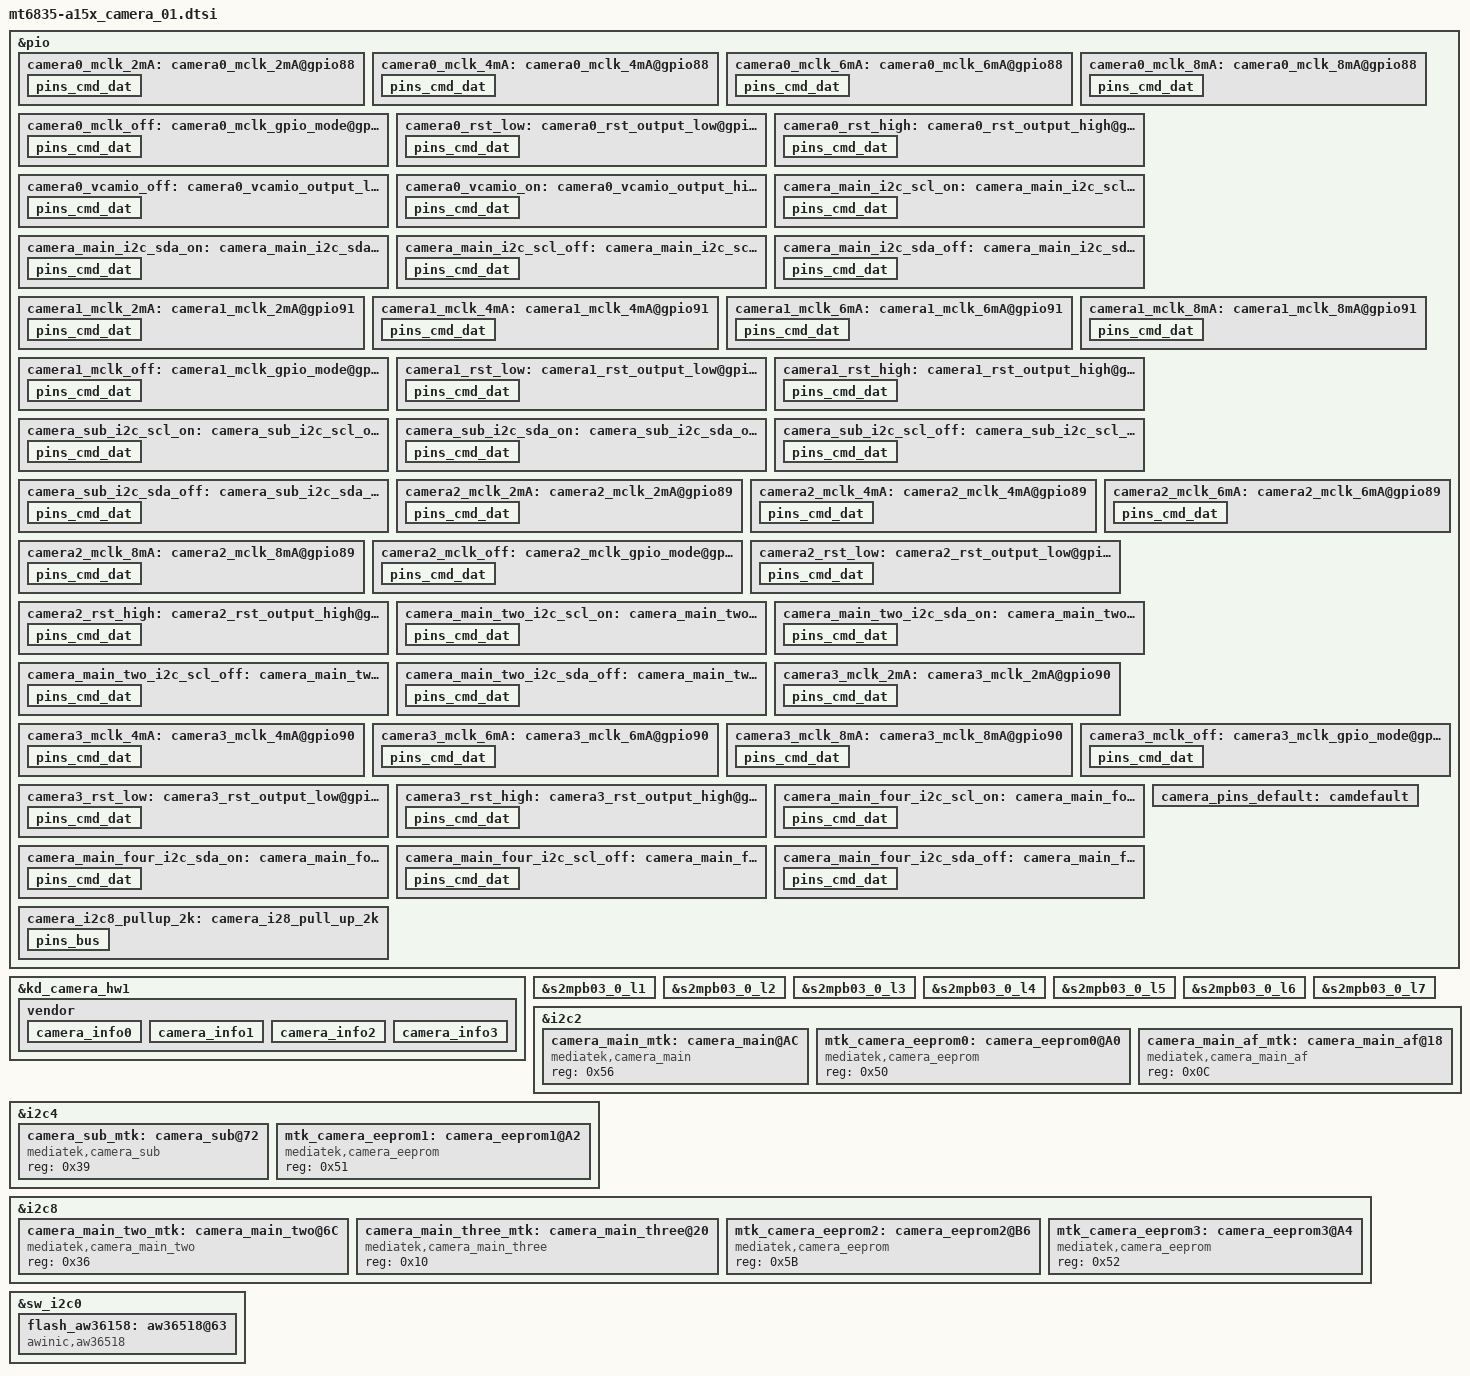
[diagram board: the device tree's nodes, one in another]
/*
 * Copyright (c) 2023 MediaTek Inc.
 *
 * This program is free software; you can redistribute it and/or modify
 * it under the terms of the GNU General Public License version 2 as
 * published by the Free Software Foundation.
 *
 * This program is distributed in the hope that it will be useful,
 * but WITHOUT ANY WARRANTY; without even the implied warranty of
 * MERCHANTABILITY or FITNESS FOR A PARTICULAR PURPOSE.  See the
 * GNU General Public License for more details.
 */

/********  A15-5G Board  ***********
 *    SW          :   HW   : Sensor
 * camera0(Wide)  : RCAM1  : HI5022Q or S5KJN1
 * camera1(Front) : FCAM   : GC13A0
 * camera2(UW)    : RCAM2  : SC501CS
 * camera3(Macro) : RCAM3  : GC02M2
 ***********************************/

/* CAMERA GPIO standardization */
&pio {
	/****************  Camera0  ***************/
	// MCLK
	camera0_mclk_2mA: camera0_mclk_2mA@gpio88 {
		pins_cmd_dat {
			pinmux = <PINMUX_GPIO88__FUNC_CMMCLK0>;
			drive-strength = <0>;
		};
	};
	camera0_mclk_4mA: camera0_mclk_4mA@gpio88 {
		pins_cmd_dat {
			pinmux = <PINMUX_GPIO88__FUNC_CMMCLK0>;
			drive-strength = <1>;
		};
	};
	camera0_mclk_6mA: camera0_mclk_6mA@gpio88 {
		pins_cmd_dat {
			pinmux = <PINMUX_GPIO88__FUNC_CMMCLK0>;
			drive-strength = <2>;
		};
	};
	camera0_mclk_8mA: camera0_mclk_8mA@gpio88 {
		pins_cmd_dat {
			pinmux = <PINMUX_GPIO88__FUNC_CMMCLK0>;
			drive-strength = <3>;
		};
	};
	camera0_mclk_off: camera0_mclk_gpio_mode@gpio88 {
		pins_cmd_dat {
			pinmux = <PINMUX_GPIO88__FUNC_GPIO88>;
			drive-strength = <1>;
		};
	};

	// Reset
	camera0_rst_low: camera0_rst_output_low@gpio25 {
		pins_cmd_dat {
			pinmux = <PINMUX_GPIO25__FUNC_GPIO25>;
			output-low;
		};
	};
	camera0_rst_high: camera0_rst_output_high@gpio25 {
		pins_cmd_dat {
			pinmux = <PINMUX_GPIO25__FUNC_GPIO25>;
			output-high;
		};
	};

	// IOVDD
	camera0_vcamio_off: camera0_vcamio_output_low@gpio150 {
		pins_cmd_dat {
			pinmux = <PINMUX_GPIO150__FUNC_GPIO150>;
			output-low;
		};
	};
	camera0_vcamio_on: camera0_vcamio_output_high@gpio150 {
		pins_cmd_dat {
			pinmux = <PINMUX_GPIO150__FUNC_GPIO150>;
			output-high;
		};
	};

	// I2C
	camera_main_i2c_scl_on: camera_main_i2c_scl_on@gpio131 {
		pins_cmd_dat {
			pinmux = <PINMUX_GPIO131__FUNC_SCL2>;
			bias-disable;
		};
	};
	camera_main_i2c_sda_on: camera_main_i2c_sda_on@gpio132 {
		pins_cmd_dat {
			pinmux = <PINMUX_GPIO132__FUNC_SDA2>;
			bias-disable;
		};
	};
	camera_main_i2c_scl_off: camera_main_i2c_scl_off@gpio131 {
		pins_cmd_dat {
			pinmux = <PINMUX_GPIO131__FUNC_GPIO131>;
			bias-disable;
		};
	};
	camera_main_i2c_sda_off: camera_main_i2c_sda_off@gpio132 {
		pins_cmd_dat {
			pinmux = <PINMUX_GPIO132__FUNC_GPIO132>;
			bias-disable;
		};
	};

	/****************  Camera1  ***************/
	// MCLK
	camera1_mclk_2mA: camera1_mclk_2mA@gpio91 {
		pins_cmd_dat {
			pinmux = <PINMUX_GPIO91__FUNC_CMMCLK3>;
			drive-strength = <0>;
		};
	};
	camera1_mclk_4mA: camera1_mclk_4mA@gpio91 {
		pins_cmd_dat {
			pinmux = <PINMUX_GPIO91__FUNC_CMMCLK3>;
			drive-strength = <1>;
		};
	};
	camera1_mclk_6mA: camera1_mclk_6mA@gpio91 {
		pins_cmd_dat {
			pinmux = <PINMUX_GPIO91__FUNC_CMMCLK3>;
			drive-strength = <2>;
		};
	};
	camera1_mclk_8mA: camera1_mclk_8mA@gpio91 {
		pins_cmd_dat {
			pinmux = <PINMUX_GPIO91__FUNC_CMMCLK3>;
			drive-strength = <3>;
		};
	};
	camera1_mclk_off: camera1_mclk_gpio_mode@gpio91 {
		pins_cmd_dat {
			pinmux = <PINMUX_GPIO91__FUNC_GPIO91>;
			drive-strength = <1>;
		};
	};

	// Reset
	camera1_rst_low: camera1_rst_output_low@gpio21 {
		pins_cmd_dat {
			pinmux = <PINMUX_GPIO21__FUNC_GPIO21>;
			output-low;
		};
	};
	camera1_rst_high: camera1_rst_output_high@gpio21 {
		pins_cmd_dat {
			pinmux = <PINMUX_GPIO21__FUNC_GPIO21>;
			output-high;
		};
	};

	// I2C
	camera_sub_i2c_scl_on: camera_sub_i2c_scl_on@gpio135 {
		pins_cmd_dat {
			pinmux = <PINMUX_GPIO135__FUNC_SCL4>;
			bias-pull-up;
		};
	};
	camera_sub_i2c_sda_on: camera_sub_i2c_sda_on@gpio136 {
		pins_cmd_dat {
			pinmux = <PINMUX_GPIO136__FUNC_SDA4>;
			bias-pull-up;
		};
	};
	camera_sub_i2c_scl_off: camera_sub_i2c_scl_off@gpio135 {
		pins_cmd_dat {
			pinmux = <PINMUX_GPIO135__FUNC_GPIO135>;
			bias-pull-down;
		};
	};
	camera_sub_i2c_sda_off: camera_sub_i2c_sda_off@gpio136 {
		pins_cmd_dat {
			pinmux = <PINMUX_GPIO136__FUNC_GPIO136>;
			bias-pull-down;
		};
	};

	/****************  Camera2  ***************/
	// MCLK
	camera2_mclk_2mA: camera2_mclk_2mA@gpio89 {
		pins_cmd_dat {
			pinmux = <PINMUX_GPIO89__FUNC_CMMCLK1>;
			drive-strength = <0>;
		};
	};
	camera2_mclk_4mA: camera2_mclk_4mA@gpio89 {
		pins_cmd_dat {
			pinmux = <PINMUX_GPIO89__FUNC_CMMCLK1>;
			drive-strength = <1>;
		};
	};
	camera2_mclk_6mA: camera2_mclk_6mA@gpio89 {
		pins_cmd_dat {
			pinmux = <PINMUX_GPIO89__FUNC_CMMCLK1>;
			drive-strength = <2>;
		};
	};
	camera2_mclk_8mA: camera2_mclk_8mA@gpio89 {
		pins_cmd_dat {
			pinmux = <PINMUX_GPIO89__FUNC_CMMCLK1>;
			drive-strength = <3>;
		};
	};
	camera2_mclk_off: camera2_mclk_gpio_mode@gpio89 {
		pins_cmd_dat {
			pinmux = <PINMUX_GPIO89__FUNC_GPIO89>;
			drive-strength = <1>;
		};
	};

	// Reset
	camera2_rst_low: camera2_rst_output_low@gpio27 {
		pins_cmd_dat {
			pinmux = <PINMUX_GPIO27__FUNC_GPIO27>;
			output-low;
		};
	};
	camera2_rst_high: camera2_rst_output_high@gpio27 {
		pins_cmd_dat {
			pinmux = <PINMUX_GPIO27__FUNC_GPIO27>;
			output-high;
		};
	};

	// I2C
	camera_main_two_i2c_scl_on: camera_main_two_i2c_scl_on@gpio143 {
		pins_cmd_dat {
			pinmux = <PINMUX_GPIO143__FUNC_SCL8>;
			bias-pull-up;
		};
	};
	camera_main_two_i2c_sda_on: camera_main_two_i2c_sda_on@gpio144 {
		pins_cmd_dat {
			pinmux = <PINMUX_GPIO144__FUNC_SDA8>;
			bias-pull-up;
		};
	};
	camera_main_two_i2c_scl_off: camera_main_two_i2c_scl_off@gpio143 {
		pins_cmd_dat {
			pinmux = <PINMUX_GPIO143__FUNC_GPIO143>;
			bias-pull-down;
		};
	};
	camera_main_two_i2c_sda_off: camera_main_two_i2c_sda_off@gpio144 {
		pins_cmd_dat {
			pinmux = <PINMUX_GPIO144__FUNC_GPIO144>;
			bias-pull-down;
		};
	};

	/****************  Camera3  ***************/
	// MCLK
	camera3_mclk_2mA: camera3_mclk_2mA@gpio90 {
		pins_cmd_dat {
			pinmux = <PINMUX_GPIO90__FUNC_CMMCLK2>;
			drive-strength = <0>;
		};
	};
	camera3_mclk_4mA: camera3_mclk_4mA@gpio90 {
		pins_cmd_dat {
			pinmux = <PINMUX_GPIO90__FUNC_CMMCLK2>;
			drive-strength = <1>;
		};
	};
	camera3_mclk_6mA: camera3_mclk_6mA@gpio90 {
		pins_cmd_dat {
			pinmux = <PINMUX_GPIO90__FUNC_CMMCLK2>;
			drive-strength = <2>;
		};
	};
	camera3_mclk_8mA: camera3_mclk_8mA@gpio90 {
		pins_cmd_dat {
			pinmux = <PINMUX_GPIO90__FUNC_CMMCLK2>;
			drive-strength = <3>;
		};
	};
	camera3_mclk_off: camera3_mclk_gpio_mode@gpio90 {
		pins_cmd_dat {
			pinmux = <PINMUX_GPIO90__FUNC_GPIO90>;
			drive-strength = <1>;
		};
	};

	// Reset
	camera3_rst_low: camera3_rst_output_low@gpio26 {
		pins_cmd_dat {
			pinmux = <PINMUX_GPIO26__FUNC_GPIO26>;
			output-low;
		};
	};
	camera3_rst_high: camera3_rst_output_high@gpio26 {
		pins_cmd_dat {
			pinmux = <PINMUX_GPIO26__FUNC_GPIO26>;
			output-high;
		};
	};

	// I2C
	camera_main_four_i2c_scl_on: camera_main_four_i2c_scl_on@gpio143 {
		pins_cmd_dat {
			pinmux = <PINMUX_GPIO143__FUNC_SCL8>;
			bias-pull-up;
		};
	};
	camera_main_four_i2c_sda_on: camera_main_four_i2c_sda_on@gpio144 {
		pins_cmd_dat {
			pinmux = <PINMUX_GPIO144__FUNC_SDA8>;
			bias-pull-up;
		};
	};
	camera_main_four_i2c_scl_off: camera_main_four_i2c_scl_off@gpio143 {
		pins_cmd_dat {
			pinmux = <PINMUX_GPIO143__FUNC_GPIO143>;
			bias-pull-down;
		};
	};
	camera_main_four_i2c_sda_off: camera_main_four_i2c_sda_off@gpio144 {
		pins_cmd_dat {
			pinmux = <PINMUX_GPIO144__FUNC_GPIO144>;
			bias-pull-down;
		};
	};

	// Internal pull up(0x5:2k, 0x7:1k)
	camera_i2c8_pullup_2k: camera_i28_pull_up_2k {
		pins_bus {
			pinmux = <PINMUX_GPIO144__FUNC_SDA8>, <PINMUX_GPIO143__FUNC_SCL8>;
			bias-pull-up = <MTK_PULL_SET_RSEL_101>;
		};
	};
	/****************  Camera OIS  ***************/

	// OIS_MCU_LDO_EN

	// OIS_MCU_RST

	/****************  default  ***************/
	camera_pins_default: camdefault {
	};
};

&kd_camera_hw1 {
	pinctrl-names = "default",
			"cam0_mclk_off",
			"cam0_mclk_2mA", "cam0_mclk_4mA",
			"cam0_mclk_6mA", "cam0_mclk_8mA",
			"cam0_rst0", "cam0_rst1",
			"cam0_vcamio_off", "cam0_vcamio_on",

			"cam1_mclk_off",
			"cam1_mclk_2mA", "cam1_mclk_4mA",
			"cam1_mclk_6mA", "cam1_mclk_8mA",
			"cam1_rst0", "cam1_rst1",

			"cam2_mclk_off",
			"cam2_mclk_2mA", "cam2_mclk_4mA",
			"cam2_mclk_6mA", "cam2_mclk_8mA",
			"cam2_rst0", "cam2_rst1",

			"cam3_mclk_off",
			"cam3_mclk_2mA", "cam3_mclk_4mA",
			"cam3_mclk_6mA", "cam3_mclk_8mA",
			"cam3_rst0", "cam3_rst1";

	pinctrl-0 = <&camera_pins_default>;

	pinctrl-1 = <&camera0_mclk_off>;
	pinctrl-2 = <&camera0_mclk_2mA>;
	pinctrl-3 = <&camera0_mclk_4mA>;
	pinctrl-4 = <&camera0_mclk_6mA>;
	pinctrl-5 = <&camera0_mclk_8mA>;
	pinctrl-6 = <&camera0_rst_low>;
	pinctrl-7 = <&camera0_rst_high>;
	pinctrl-8 = <&camera0_vcamio_off>;
	pinctrl-9 = <&camera0_vcamio_on>;

	pinctrl-10 = <&camera1_mclk_off>;
	pinctrl-11 = <&camera1_mclk_2mA>;
	pinctrl-12 = <&camera1_mclk_4mA>;
	pinctrl-13 = <&camera1_mclk_6mA>;
	pinctrl-14 = <&camera1_mclk_8mA>;
	pinctrl-15 = <&camera1_rst_low>;
	pinctrl-16 = <&camera1_rst_high>;

	pinctrl-17 = <&camera2_mclk_off>;
	pinctrl-18 = <&camera2_mclk_2mA>;
	pinctrl-19 = <&camera2_mclk_4mA>;
	pinctrl-20 = <&camera2_mclk_6mA>;
	pinctrl-21 = <&camera2_mclk_8mA>;
	pinctrl-22 = <&camera2_rst_low>;
	pinctrl-23 = <&camera2_rst_high>;

	pinctrl-24 = <&camera3_mclk_off>;
	pinctrl-25 = <&camera3_mclk_2mA>;
	pinctrl-26 = <&camera3_mclk_4mA>;
	pinctrl-27 = <&camera3_mclk_6mA>;
	pinctrl-28 = <&camera3_mclk_8mA>;
	pinctrl-29 = <&camera3_rst_low>;
	pinctrl-30 = <&camera3_rst_high>;

	/********* Regulator setting **************/
	// Camera0
	cam0_vcamd-supply  = <&s2mpb03_0_l1>;
	cam0_vcama-supply  = <&s2mpb03_0_l5>;
	cam0_vcamio-supply = <&s2mpb03_0_l3>;
	cam0_vcamaf-supply = <&s2mpb03_0_l7>;

	// Camera1
	cam1_vcamd-supply  = <&s2mpb03_0_l2>;
	cam1_vcama-supply  = <&s2mpb03_0_l6>;
	cam1_vcamio-supply = <&s2mpb03_0_l3>;
	cam1_vcamd1-supply = <&s2mpb03_0_l4>;

	// Camera2
	cam2_vcamd-supply  = <&s2mpb03_0_l4>;
	cam2_vcama-supply  = <&s2mpb03_0_l6>;
	cam2_vcamio-supply = <&s2mpb03_0_l3>;

	// Camera3
	cam3_vcama-supply  = <&s2mpb03_0_l6>;
	cam3_vcamio-supply = <&s2mpb03_0_l3>;
	cam3_vcamd1-supply = <&s2mpb03_0_l4>;

	status = "okay";
	vendor {
		rear_sensor_id = <120>;     /* SENSOR_NAME_HI5022Q */
		front_sensor_id = <121>;    /* SENSOR_NAME_GC13A0 */
		rear2_sensor_id = <210>;    /* SENSOR_NAME_SC501CS */
		rear3_sensor_id = <211>;    /* SENSOR_NAME_GC02M2 */

		use_dualcam_set_cal;
		use_module_check;

		//skip_cal_loading;         /* for test without cal loading */
		check_final_cam_module;   /* use after DVR */
		max_supported_camera = <4>;
		supported_cameraId = <0 1 50 54>; /* REAR, FRONT, REAR2, REAR3 */

		max_camera_num = <4>;
		camera_info0 {             /* 0 : rear - HI5022Q */
			isp = <0>;             /* 0 : INT , 1 : EXT , 2 : SOC */
			cal_memory = <2>;      /* 0 : N , 1 : FROM , 2 : EEPROM , 3 : OTP  */
			read_version = <0>;    /* 0 : SYSFS , 1 : CAMON */
			core_voltage = <0>;    /* 0 : N , 1 : Y  */
			upgrade = <0>;         /* 0 : N , 1 : SYSFS , 2 : CAMON */
			companion = <0>;       /* 0 : N , 1 : Y  */
			ois = <0>;             /* 0 : N , 1 : Y  */
			valid = <1>;           /* 0 : INVALID, 1 : VALID */
			dual_open = <0>;       /* 0 : SINGLE_OPEN , 1 : DUAL_OPEN */
			position = <0>;        /* 0 : Rear, 1:Front, 2:Rear2, 3:Front2, 4:Rear3, 6:Rear4 */
			//includes_sub = <4>;    /* include this for common eeprom. <_position_> - position of the sub camera */
			afcal_type=<20>;       /* output format - 1: Near, Middle..., Far , 20: Near, Far, Middle... */
			use_adaptive_mipi=<1>;  /* 0 : N, 1 : Y */
		};
		camera_info1 {             /* 1 : front1 - GC13A0 */
			isp = <0>;             /* 0 : INT , 1 : EXT , 2 : SOC */
			cal_memory = <2>;      /* 0 : N , 1 : FROM , 2 : EEPROM , 3 : OTP  */
			read_version = <0>;    /* 0 : SYSFS , 1 : CAMON */
			core_voltage = <0>;    /* 0 : N , 1 : Y  */
			upgrade = <0>;         /* 0 : N , 1 : SYSFS , 2 : CAMON */
			companion = <0>;       /* 0 : N , 1 : Y  */
			ois = <0>;             /* 0 : N , 1 : Y  */
			valid = <1>;           /* 0 : INVALID, 1 : VALID */
			dual_open = <0>;       /* 0 : SINGLE_OPEN , 1 : DUAL_OPEN */
			position = <1>;        /* 0 : Rear, 1:Front, 2:Rear2, 3:Front2, 4:Rear3, 6:Rear4 */
			use_adaptive_mipi=<1>;  /* 0 : N, 1 : Y */
		};
		camera_info2 {             /* 2 : rear2 - SC501CS */
			isp = <0>;             /* 0 : INT , 1 : EXT , 2 : SOC */
			cal_memory = <3>;      /* 0 : N , 1 : FROM , 2 : EEPROM , 3 : OTP  */
			read_version = <0>;    /* 0 : SYSFS , 1 : CAMON */
			core_voltage = <0>;    /* 0 : N , 1 : Y  */
			upgrade = <0>;         /* 0 : N , 1 : SYSFS , 2 : CAMON */
			companion = <0>;       /* 0 : N , 1 : Y  */
			ois = <0>;             /* 0 : N , 1 : Y  */
			valid = <1>;           /* 0 : INVALID, 1 : VALID */
			dual_open = <0>;       /* 0 : SINGLE_OPEN , 1 : DUAL_OPEN */
			position = <2>;        /* 0 : Rear, 1:Front, 2:Rear2, 3:Front2, 4:Rear3, 6:Rear4 */
			use_adaptive_mipi=<0>;  /* 0 : N, 1 : Y */
		};
		camera_info3{             /* 3 : rear3 - GC02M2 */
			isp = <0>;             /* 0 : INT , 1 : EXT , 2 : SOC */
			cal_memory = <2>;      /* 0 : N , 1 : FROM , 2 : EEPROM , 3 : OTP  */
			read_version = <0>;    /* 0 : SYSFS , 1 : CAMON */
			core_voltage = <0>;    /* 0 : N , 1 : Y  */
			upgrade = <0>;         /* 0 : N , 1 : SYSFS , 2 : CAMON */
			companion = <0>;       /* 0 : N , 1 : Y  */
			ois = <0>;             /* 0 : N , 1 : Y  */
			valid = <1>;           /* 0 : INVALID, 1 : VALID */
			dual_open = <0>;       /* 0 : SINGLE_OPEN , 1 : DUAL_OPEN */
			position = <4>;        /* 0 : Rear, 1:Front, 2:Rear2, 3:Front2, 4:Rear3, 6:Rear4 */
			use_adaptive_mipi=<0>;  /* 0 : N, 1 : Y */
		};
	};
};
/* CAMERA GPIO end */

/* CAMERA OIS */

/* CAMERA OIS end */

/* CAM PMIC */
&s2mpb03_0_l1 {
	regulator-min-microvolt = <1050000>;
	regulator-max-microvolt = <1200000>;
};
&s2mpb03_0_l2 {
	regulator-min-microvolt = <1050000>;
	regulator-max-microvolt = <1200000>;
};
&s2mpb03_0_l3 {
	regulator-min-microvolt = <1800000>;
	regulator-max-microvolt = <1800000>;
};
&s2mpb03_0_l4 {
	regulator-min-microvolt = <1200000>;
	regulator-max-microvolt = <1200000>;
};
&s2mpb03_0_l5 {
	regulator-min-microvolt = <2800000>;
	regulator-max-microvolt = <2800000>;
};
&s2mpb03_0_l6 {
	regulator-min-microvolt = <2800000>;
	regulator-max-microvolt = <2800000>;
};
&s2mpb03_0_l7 {
	regulator-min-microvolt = <2800000>;
	regulator-max-microvolt = <2800000>;
};

/*************************
 *     Cmaera I2C
 *************************/
&i2c2 {
	status = "okay";
	#address-cells = <1>;
	#size-cells = <0>;
	clock-frequency = <1000000>;
	mediatek,use-open-drain;

	camera_main_mtk:camera_main@AC{
		compatible = "mediatek,camera_main";
		reg = <0x56>;
		status = "okay";
	};
	mtk_camera_eeprom0:camera_eeprom0@A0 {
		compatible = "mediatek,camera_eeprom";
		reg = <0x50>;
		status = "okay";
	};
	camera_main_af_mtk:camera_main_af@18 {
		compatible = "mediatek,camera_main_af";
		reg = <0x0C>;
		status = "okay";
	};
};

&i2c4 {
	status = "okay";
	#address-cells = <1>;
	#size-cells = <0>;
	clock-frequency = <1000000>;
	mediatek,use-open-drain;
	camera_sub_mtk:camera_sub@72 {
		compatible = "mediatek,camera_sub";
		reg = <0x39>;
		status = "okay";
	};
	mtk_camera_eeprom1:camera_eeprom1@A2 {
		compatible = "mediatek,camera_eeprom";
		reg = <0x51>;
		status = "okay";
	};
};

&i2c8 {
	status = "okay";
	#address-cells = <1>;
	#size-cells = <0>;
	clock-frequency = <400000>;
	mediatek,use-open-drain;

	pinctrl-names = "default";
	pinctrl-0 = <&camera_i2c8_pullup_2k>;

	camera_main_two_mtk:camera_main_two@6C{
		compatible = "mediatek,camera_main_two";
		reg = <0x36>;
		status = "okay";
	};
	camera_main_three_mtk:camera_main_three@20 {
		compatible = "mediatek,camera_main_three";
		reg = <0x10>;
		status = "okay";
	};
	mtk_camera_eeprom2:camera_eeprom2@B6 {
		compatible = "mediatek,camera_eeprom";
		reg = <0x5B>;
		status = "okay";
	};
	mtk_camera_eeprom3:camera_eeprom3@A4 {
		compatible = "mediatek,camera_eeprom";
		reg = <0x52>;
		status = "okay";
	};
};

/*************************
 *     Flash LED
 *************************/
&sw_i2c0 {
	#address-cells = <1>;
	#size-cells = <0>;
	status = "okay";
	flash_aw36158:aw36518@63 {
		compatible = "awinic,aw36518";
		reg = <0x63>;
		is_flash = "Flash";
		status = "okay";
		flash-gpio = <&pio 149 0>;
		torch_level_1_cur = <50>;
		torch_level_2_cur = <75>;
		torch_level_3_cur = <100>;
		torch_level_4_cur = <175>;
		torch_level_5_cur = <225>;
		pre_flash_cur = <150>;
		main_flash_cur = <1250>;
		video_torch_cur = <150>;
	};
};

